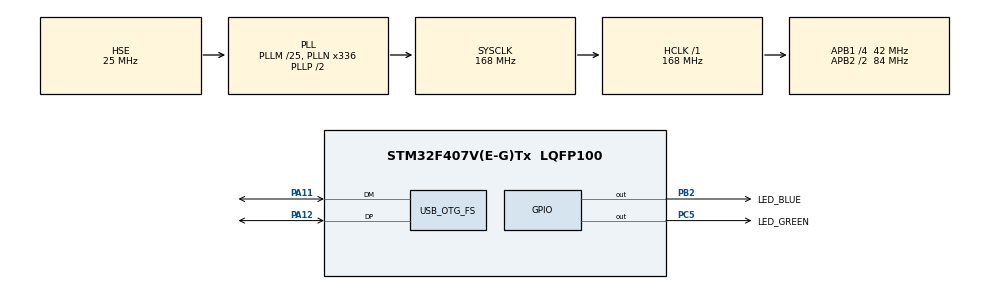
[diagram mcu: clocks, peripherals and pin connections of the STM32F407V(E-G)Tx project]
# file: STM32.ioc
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Mcu.Family=STM32F4
Mcu.Name=STM32F407V(E-G)Tx
Mcu.Package=LQFP100
NVIC.OTG_FS_IRQn=true\:0\:0\:false\:false\:true\:false\:true\:true
NVIC.PriorityGroup=NVIC_PRIORITYGROUP_4
PA11.Mode=Device_Only
PA11.Signal=USB_OTG_FS_DM
PA12.Mode=Device_Only
PA12.Signal=USB_OTG_FS_DP
PA13.Mode=Serial_Wire
PA13.Signal=SYS_JTMS-SWDIO
PA14.Mode=Serial_Wire
PA14.Signal=SYS_JTCK-SWCLK
PB2.GPIO_Label=LED_BLUE
PB2.GPIO_PuPd=GPIO_PULLUP
PB2.PinState=GPIO_PIN_RESET
PB2.Signal=GPIO_Output
PC5.GPIO_Label=LED_GREEN
PC5.Signal=GPIO_Output
PH0-OSC_IN.Mode=HSE-External-Oscillator
PH0-OSC_IN.Signal=RCC_OSC_IN
PH1-OSC_OUT.Mode=HSE-External-Oscillator
PH1-OSC_OUT.Signal=RCC_OSC_OUT
ProjectManager.HeapSize=0x400
ProjectManager.StackSize=0x1000
ProjectManager.TargetToolchain=MDK-ARM V5.32
RCC.48MHZClocksFreq_Value=48000000
RCC.AHBFreq_Value=168000000
RCC.APB1CLKDivider=RCC_HCLK_DIV4
RCC.APB1Freq_Value=42000000
RCC.APB1TimFreq_Value=84000000
RCC.APB2CLKDivider=RCC_HCLK_DIV2
RCC.APB2Freq_Value=84000000
RCC.APB2TimFreq_Value=168000000
RCC.CortexFreq_Value=168000000
RCC.HCLKFreq_Value=168000000
RCC.HSE_VALUE=25000000
RCC.HSI_VALUE=16000000
RCC.LSE_VALUE=32768
RCC.PLLM=25
RCC.PLLN=336
RCC.PLLQ=7
RCC.SYSCLKFreq_VALUE=168000000
RCC.SYSCLKSource=RCC_SYSCLKSOURCE_PLLCLK
RCC.VCOOutputFreq_Value=336000000
USB_DEVICE.APP_RX_DATA_SIZE-CDC_FS=1024
USB_DEVICE.APP_TX_DATA_SIZE-CDC_FS=1024
USB_DEVICE.CLASS_NAME_FS=CDC
USB_DEVICE.VirtualMode-CDC_FS=Cdc
USB_DEVICE.VirtualModeFS=Cdc_FS
USB_OTG_FS.VirtualMode=Device_Only
VP_USB_DEVICE_VS_USB_DEVICE_CDC_FS.Mode=CDC_FS
board=custom

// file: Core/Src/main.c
/* USER CODE BEGIN Header */
/**==================================================================================================================
 ** 【文件名称】  main.c
 ** 【功能测试】  USB 虚拟串口（CDC）收发通信
 **==================================================================================================================
 ** 【实验平台】  STM32F407 + KEIL5.31 + HAL库
 **
 ** 【实验操作】  1. 硬件接线
 **                  开发板 USB 接口直接连接电脑
 **                  无需额外接线，自动枚举为虚拟串口
 **
 **               2. 电脑端操作
 **                  打开串口助手，选择 STMicroelectronics Virtual COM Port
 **                  无需设置波特率，USB 虚拟串口自动适配
 **
 **               3. 测试现象
 **                  电脑发送数据 → 开发板接收并自动回显
 **                  开发板每 500ms 自动发送测试字符串 + LED 闪烁
 **
 ** 【核心说明】  1. 基于 USB CDC 实现虚拟串口，免串口芯片、免电平转换
 **               2. 支持中英文、ASCII 字符串高速收发
 **               3. 电脑端免驱（WIN10/11 自动识别）
 **               4. 发送函数：CDC_Transmit_FS()
 **               5. 接收数据存入 myUsbRxData，长度存入 myUsbRxNum
 **
 ** 【划 重 点】  1. USB 时钟必须配置正确（需 48MHz）
 **               2. 接收完成后需手动清 0 标志：myUsbRxNum
 **               3. 连续发送需注意间隔，避免数据覆盖
 **
 ** 【更新记录】  2026-03-27  规范注释、优化排版、统一格式
 **
 ** 【备注说明】  版权归魔女科技所有，请勿商用，谢谢！
 **               https://demoboard.taobao.com
 **==================================================================================================================*/
/* USER CODE END Header */
#include "main.h"
#include "usb_device.h"
#include "gpio.h"

/* USER CODE BEGIN Includes */

#include "usbd_cdc_if.h"

/* USER CODE END Includes */

void SystemClock_Config(void);

int main(void)
{

    /* USER CODE BEGIN 1 */

    /* 说明：
     * 1. 不要删除CubeMX生成的注释行（形如 USER CODE BEGIN/END），这些注释用于代码重新生成时的定位
     * 2. 所有用户自定义代码必须写在对应的BEGIN与END注释行之间，否则重新生成时会被覆盖
     * 3. 主要初始化函数说明：
     *    - HAL_Init()            初始化HAL库，配置中断优先级、系统时基等
     *    - SystemClock_Config()  配置系统时钟
     *    - MX_GPIO_Init()        初始化GPIO引脚（仅包含推挽输出、中断触发等配置）
     *    - 外设功能引脚（如UART、SPI等）的初始化在各自的功能文件中
     */

    /* USER CODE END 1 */

    /* MCU Configuration--------------------------------------------------------*/

    /* Reset of all peripherals, Initializes the Flash interface and the Systick. */
    HAL_Init();

    /* Configure the system clock */
    SystemClock_Config();

    /* Initialize all configured peripherals */
    MX_GPIO_Init();
    MX_USB_DEVICE_Init();

    /* Infinite loop */
    while (1)
    {

        /* USER CODE BEGIN 3 */

        // 判断接收
        if (myUsbRxNum)
        {
            static char myStr[100] = { 0 };
            sprintf(myStr, "\r\r收到 %d 个字节；\r内容是：%s\r\r", myUsbRxNum, (char *)myUsbRxData); // 格式化字符串
            CDC_Transmit_FS((uint8_t *)myStr, strlen(myStr));                                        // 发送
            myUsbRxNum = 0;                                                                          // 清0接收字节
        }

        // 每500ms 发送一次测试数据
        static uint32_t lastTime_500ms = 0;               // 定义静态变量，用于记录上次执行这个任务的时间点(单位：毫秒)
        if (HAL_GetTick() - lastTime_500ms >= 500)        // 检查当前时间距离上次执行是否已经过了500ms; HAL_GetTick()是获取启动后经过的毫秒数;
        {
            CDC_Transmit_FS((uint8_t *)"Hello\r", 6);     // 发送数据; 参数：数据地址、字节数
            CDC_Transmit_FS((uint8_t *)"借点钱\r", 7);    // 发送数据; 参数：数据地址、字节数
            HAL_GPIO_TogglePin(GPIOC, GPIO_PIN_5);        // 闪烁绿色LED, 便于观察程序是否运行、卡死
            lastTime_500ms =   HAL_GetTick();             // 记录当前时间，作为新的基准点，为下一次判断做准备
        }
    }
    /* USER CODE END 3 */
}

void SystemClock_Config(void)
{
    RCC_OscInitTypeDef RCC_OscInitStruct = {0};
    RCC_ClkInitTypeDef RCC_ClkInitStruct = {0};

    /** Configure the main internal regulator output voltage
    */
    __HAL_RCC_PWR_CLK_ENABLE();
    __HAL_PWR_VOLTAGESCALING_CONFIG(PWR_REGULATOR_VOLTAGE_SCALE1);

    /** Initializes the RCC Oscillators according to the specified parameters
    * in the RCC_OscInitTypeDef structure.
    */
    RCC_OscInitStruct.OscillatorType = RCC_OSCILLATORTYPE_HSE;
    RCC_OscInitStruct.HSEState = RCC_HSE_ON;
    RCC_OscInitStruct.PLL.PLLState = RCC_PLL_ON;
    RCC_OscInitStruct.PLL.PLLSource = RCC_PLLSOURCE_HSE;
    RCC_OscInitStruct.PLL.PLLM = 25;
    RCC_OscInitStruct.PLL.PLLN = 336;
    RCC_OscInitStruct.PLL.PLLP = RCC_PLLP_DIV2;
    RCC_OscInitStruct.PLL.PLLQ = 7;
    if (HAL_RCC_OscConfig(&RCC_OscInitStruct) != HAL_OK)
    {
        Error_Handler();
    }

    /** Initializes the CPU, AHB and APB buses clocks
    */
    RCC_ClkInitStruct.ClockType = RCC_CLOCKTYPE_HCLK | RCC_CLOCKTYPE_SYSCLK
                                  | RCC_CLOCKTYPE_PCLK1 | RCC_CLOCKTYPE_PCLK2;
    RCC_ClkInitStruct.SYSCLKSource = RCC_SYSCLKSOURCE_PLLCLK;
    RCC_ClkInitStruct.AHBCLKDivider = RCC_SYSCLK_DIV1;
    RCC_ClkInitStruct.APB1CLKDivider = RCC_HCLK_DIV4;
    RCC_ClkInitStruct.APB2CLKDivider = RCC_HCLK_DIV2;

    if (HAL_RCC_ClockConfig(&RCC_ClkInitStruct, FLASH_LATENCY_5) != HAL_OK)
    {
        Error_Handler();
    }
}

void Error_Handler(void)
{
    __disable_irq();
    while (1)
    {
    }
}
